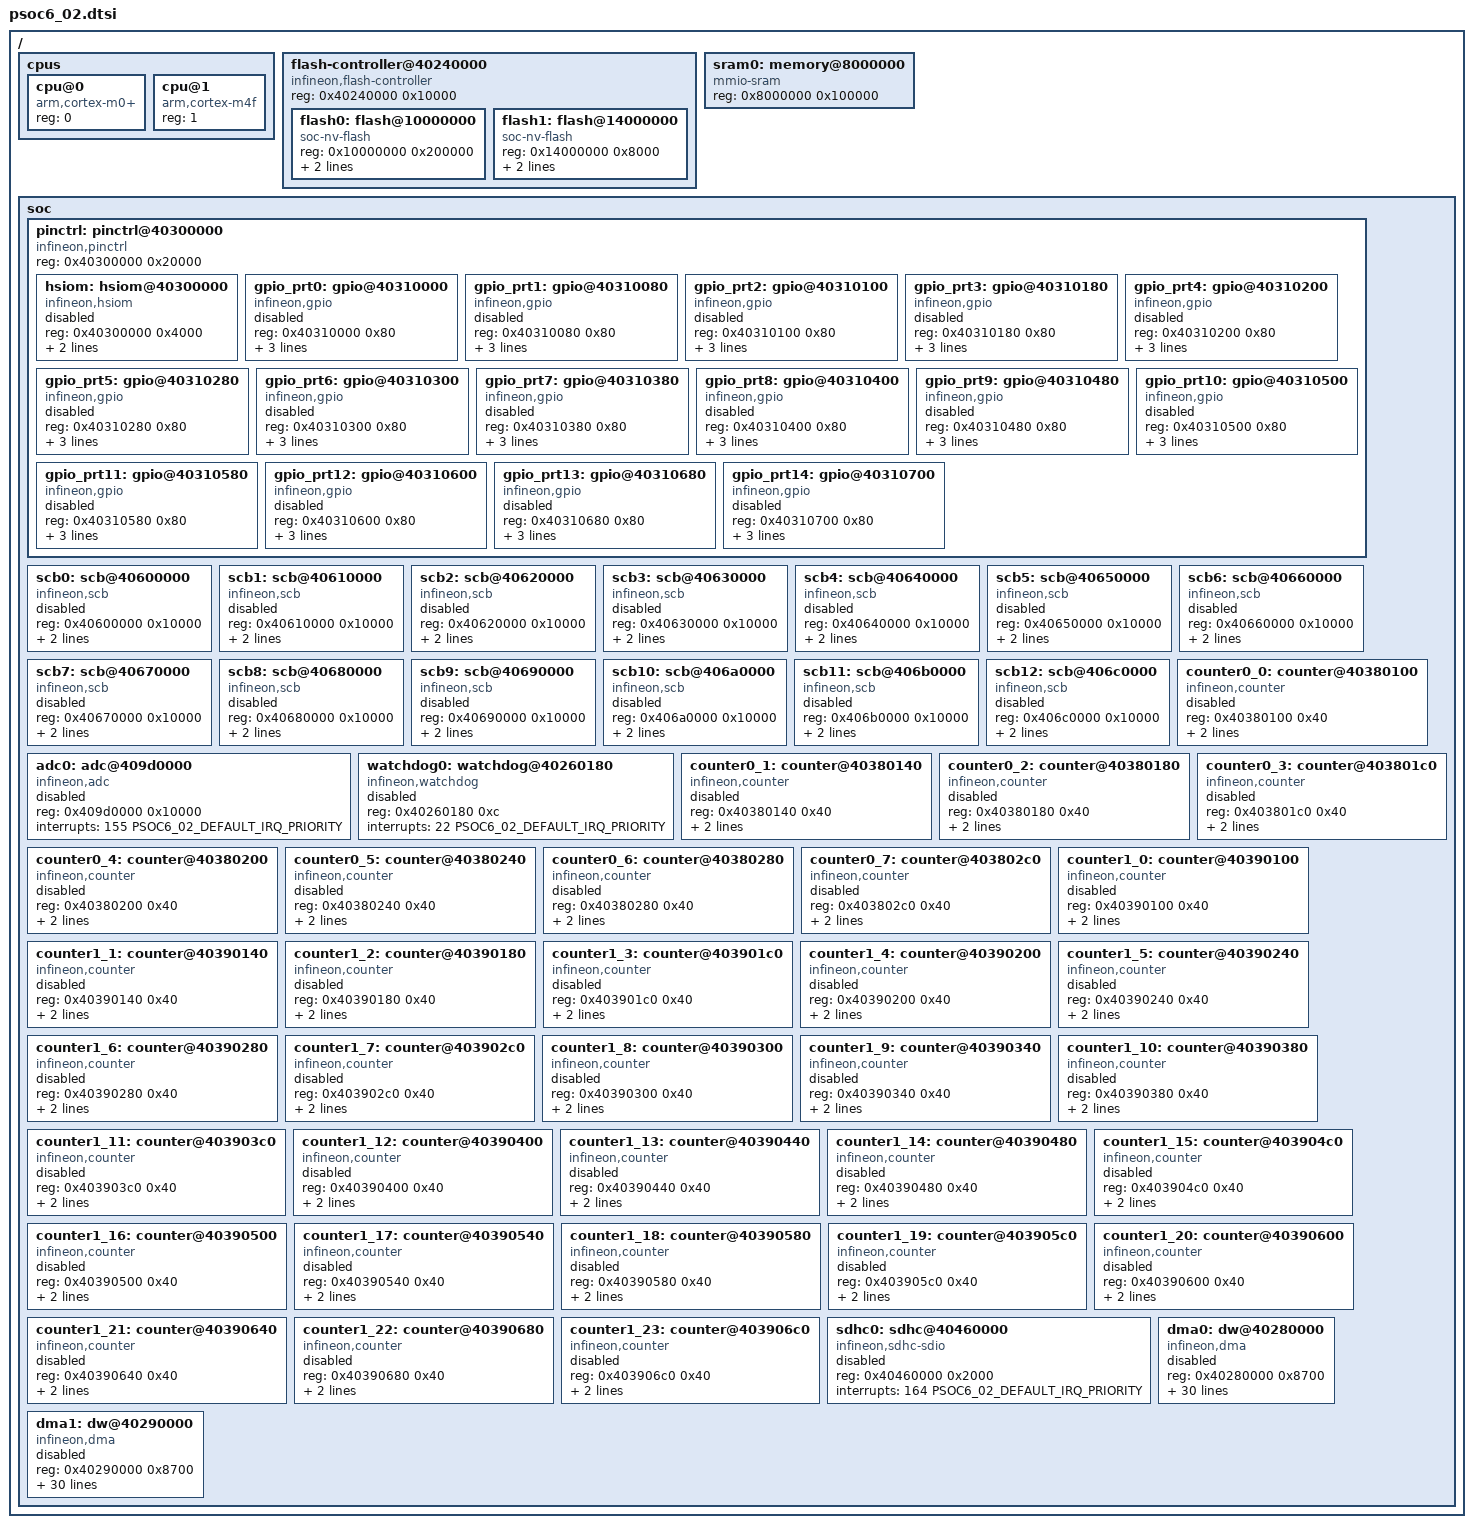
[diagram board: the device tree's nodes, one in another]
/*
 * Copyright (c) 2023 Cypress Semiconductor Corporation (an Infineon company) or
 * an affiliate of Cypress Semiconductor Corporation
 *
 * SPDX-License-Identifier: Apache-2.0
 */

#include <mem.h>

#ifndef PSOC6_02_DEFAULT_IRQ_PRIORITY
#define PSOC6_02_DEFAULT_IRQ_PRIORITY 6
#endif

/ {
	cpus {
		#address-cells = <1>;
		#size-cells = <0>;

		cpu@0 {
			device_type = "cpu";
			compatible = "arm,cortex-m0+";
			reg = <0>;
		};

		cpu@1 {
			device_type = "cpu";
			compatible = "arm,cortex-m4f";
			reg = <1>;
		};
	};

	flash-controller@40240000 {
		compatible = "infineon,flash-controller";
		reg = <0x40240000 0x10000>;
		#address-cells = <1>;
		#size-cells = <1>;

		flash0: flash@10000000 {
			compatible = "soc-nv-flash";
			reg = <0x10000000 0x200000>;
			write-block-size = <512>;
			erase-block-size = <512>;
		};

		flash1: flash@14000000 {
			compatible = "soc-nv-flash";
			reg = <0x14000000 0x8000>;
			write-block-size = <512>;
			erase-block-size = <512>;
		};
	};

	sram0: memory@8000000 {
		compatible = "mmio-sram";
		reg = <0x8000000 0x100000>;
	};

	soc {
		pinctrl: pinctrl@40300000 {
			compatible = "infineon,pinctrl";
			reg = <0x40300000 0x20000>;
			#address-cells = <1>;
			#size-cells = <0>;

			hsiom: hsiom@40300000 {
				compatible = "infineon,hsiom";
				reg = <0x40300000 0x4000>;
				interrupts = <15 PSOC6_02_DEFAULT_IRQ_PRIORITY>,
							<16 PSOC6_02_DEFAULT_IRQ_PRIORITY>;
				status = "disabled";
			};

			gpio_prt0: gpio@40310000 {
				compatible = "infineon,gpio";
				reg = <0x40310000 0x80>;
				interrupts = <0 PSOC6_02_DEFAULT_IRQ_PRIORITY>;
				gpio-controller;
				ngpios = <6>;
				status = "disabled";
				#gpio-cells = <2>;
			};

			gpio_prt1: gpio@40310080 {
				compatible = "infineon,gpio";
				reg = <0x40310080 0x80>;
				interrupts = <1 PSOC6_02_DEFAULT_IRQ_PRIORITY>;
				gpio-controller;
				ngpios = <6>;
				status = "disabled";
				#gpio-cells = <2>;
			};

			gpio_prt2: gpio@40310100 {
				compatible = "infineon,gpio";
				reg = <0x40310100 0x80>;
				interrupts = <2 PSOC6_02_DEFAULT_IRQ_PRIORITY>;
				gpio-controller;
				ngpios = <8>;
				status = "disabled";
				#gpio-cells = <2>;
			};

			gpio_prt3: gpio@40310180 {
				compatible = "infineon,gpio";
				reg = <0x40310180 0x80>;
				interrupts = <3 PSOC6_02_DEFAULT_IRQ_PRIORITY>;
				gpio-controller;
				ngpios = <6>;
				status = "disabled";
				#gpio-cells = <2>;
			};

			gpio_prt4: gpio@40310200 {
				compatible = "infineon,gpio";
				reg = <0x40310200 0x80>;
				interrupts = <4 PSOC6_02_DEFAULT_IRQ_PRIORITY>;
				gpio-controller;
				ngpios = <2>;
				status = "disabled";
				#gpio-cells = <2>;
			};

			gpio_prt5: gpio@40310280 {
				compatible = "infineon,gpio";
				reg = <0x40310280 0x80>;
				interrupts = <5 PSOC6_02_DEFAULT_IRQ_PRIORITY>;
				gpio-controller;
				ngpios = <8>;
				status = "disabled";
				#gpio-cells = <2>;
			};

			gpio_prt6: gpio@40310300 {
				compatible = "infineon,gpio";
				reg = <0x40310300 0x80>;
				interrupts = <6 PSOC6_02_DEFAULT_IRQ_PRIORITY>;
				gpio-controller;
				ngpios = <8>;
				status = "disabled";
				#gpio-cells = <2>;
			};

			gpio_prt7: gpio@40310380 {
				compatible = "infineon,gpio";
				reg = <0x40310380 0x80>;
				interrupts = <7 PSOC6_02_DEFAULT_IRQ_PRIORITY>;
				gpio-controller;
				ngpios = <8>;
				status = "disabled";
				#gpio-cells = <2>;
			};

			gpio_prt8: gpio@40310400 {
				compatible = "infineon,gpio";
				reg = <0x40310400 0x80>;
				interrupts = <8 PSOC6_02_DEFAULT_IRQ_PRIORITY>;
				gpio-controller;
				ngpios = <8>;
				status = "disabled";
				#gpio-cells = <2>;
			};

			gpio_prt9: gpio@40310480 {
				compatible = "infineon,gpio";
				reg = <0x40310480 0x80>;
				interrupts = <9 PSOC6_02_DEFAULT_IRQ_PRIORITY>;
				gpio-controller;
				ngpios = <8>;
				status = "disabled";
				#gpio-cells = <2>;
			};

			gpio_prt10: gpio@40310500 {
				compatible = "infineon,gpio";
				reg = <0x40310500 0x80>;
				interrupts = <10 PSOC6_02_DEFAULT_IRQ_PRIORITY>;
				gpio-controller;
				ngpios = <8>;
				status = "disabled";
				#gpio-cells = <2>;
			};

			gpio_prt11: gpio@40310580 {
				compatible = "infineon,gpio";
				reg = <0x40310580 0x80>;
				interrupts = <11 PSOC6_02_DEFAULT_IRQ_PRIORITY>;
				gpio-controller;
				ngpios = <8>;
				status = "disabled";
				#gpio-cells = <2>;
			};

			gpio_prt12: gpio@40310600 {
				compatible = "infineon,gpio";
				reg = <0x40310600 0x80>;
				interrupts = <12 PSOC6_02_DEFAULT_IRQ_PRIORITY>;
				gpio-controller;
				ngpios = <8>;
				status = "disabled";
				#gpio-cells = <2>;
			};

			gpio_prt13: gpio@40310680 {
				compatible = "infineon,gpio";
				reg = <0x40310680 0x80>;
				interrupts = <13 PSOC6_02_DEFAULT_IRQ_PRIORITY>;
				gpio-controller;
				ngpios = <8>;
				status = "disabled";
				#gpio-cells = <2>;
			};

			gpio_prt14: gpio@40310700 {
				compatible = "infineon,gpio";
				reg = <0x40310700 0x80>;
				interrupts = <14 PSOC6_02_DEFAULT_IRQ_PRIORITY>;
				gpio-controller;
				ngpios = <2>;
				status = "disabled";
				#gpio-cells = <2>;
			};
		};

		scb0: scb@40600000 {
			compatible = "infineon,scb";
			reg = <0x40600000 0x10000>;
			#address-cells = <1>;
			#size-cells = <0>;
			interrupts = <39 PSOC6_02_DEFAULT_IRQ_PRIORITY>;
			clk-dst = <0x0>;
			status = "disabled";
		};

		scb1: scb@40610000 {
			compatible = "infineon,scb";
			reg = <0x40610000 0x10000>;
			#address-cells = <1>;
			#size-cells = <0>;
			interrupts = <40 PSOC6_02_DEFAULT_IRQ_PRIORITY>;
			clk-dst = <0x1>;
			status = "disabled";
		};

		scb2: scb@40620000 {
			compatible = "infineon,scb";
			reg = <0x40620000 0x10000>;
			#address-cells = <1>;
			#size-cells = <0>;
			interrupts = <41 PSOC6_02_DEFAULT_IRQ_PRIORITY>;
			clk-dst = <0x2>;
			status = "disabled";
		};

		scb3: scb@40630000 {
			compatible = "infineon,scb";
			reg = <0x40630000 0x10000>;
			#address-cells = <1>;
			#size-cells = <0>;
			interrupts = <42 PSOC6_02_DEFAULT_IRQ_PRIORITY>;
			clk-dst = <0x3>;
			status = "disabled";
		};

		scb4: scb@40640000 {
			compatible = "infineon,scb";
			reg = <0x40640000 0x10000>;
			#address-cells = <1>;
			#size-cells = <0>;
			interrupts = <43 PSOC6_02_DEFAULT_IRQ_PRIORITY>;
			clk-dst = <0x4>;
			status = "disabled";
		};

		scb5: scb@40650000 {
			compatible = "infineon,scb";
			reg = <0x40650000 0x10000>;
			#address-cells = <1>;
			#size-cells = <0>;
			interrupts = <44 PSOC6_02_DEFAULT_IRQ_PRIORITY>;
			clk-dst = <0x5>;
			status = "disabled";
		};

		scb6: scb@40660000 {
			compatible = "infineon,scb";
			reg = <0x40660000 0x10000>;
			#address-cells = <1>;
			#size-cells = <0>;
			interrupts = <45 PSOC6_02_DEFAULT_IRQ_PRIORITY>;
			clk-dst = <0x6>;
			status = "disabled";
		};

		scb7: scb@40670000 {
			compatible = "infineon,scb";
			reg = <0x40670000 0x10000>;
			#address-cells = <1>;
			#size-cells = <0>;
			interrupts = <46 PSOC6_02_DEFAULT_IRQ_PRIORITY>;
			clk-dst = <0x7>;
			status = "disabled";
		};

		scb8: scb@40680000 {
			compatible = "infineon,scb";
			reg = <0x40680000 0x10000>;
			#address-cells = <1>;
			#size-cells = <0>;
			interrupts = <18 PSOC6_02_DEFAULT_IRQ_PRIORITY>;
			clk-dst = <0x8>;
			status = "disabled";
		};

		scb9: scb@40690000 {
			compatible = "infineon,scb";
			reg = <0x40690000 0x10000>;
			#address-cells = <1>;
			#size-cells = <0>;
			interrupts = <47 PSOC6_02_DEFAULT_IRQ_PRIORITY>;
			clk-dst = <0x9>;
			status = "disabled";
		};

		scb10: scb@406a0000 {
			compatible = "infineon,scb";
			reg = <0x406a0000 0x10000>;
			#address-cells = <1>;
			#size-cells = <0>;
			interrupts = <48 PSOC6_02_DEFAULT_IRQ_PRIORITY>;
			clk-dst = <0xa>;
			status = "disabled";
		};

		scb11: scb@406b0000 {
			compatible = "infineon,scb";
			reg = <0x406b0000 0x10000>;
			#address-cells = <1>;
			#size-cells = <0>;
			interrupts = <49 PSOC6_02_DEFAULT_IRQ_PRIORITY>;
			clk-dst = <0xb>;
			status = "disabled";
		};

		scb12: scb@406c0000 {
			compatible = "infineon,scb";
			reg = <0x406c0000 0x10000>;
			#address-cells = <1>;
			#size-cells = <0>;
			interrupts = <50 PSOC6_02_DEFAULT_IRQ_PRIORITY>;
			clk-dst = <0xc>;
			status = "disabled";
		};

		adc0: adc@409d0000 {
			compatible = "infineon,adc";
			reg = <0x409d0000 0x10000>;
			interrupts = <155 PSOC6_02_DEFAULT_IRQ_PRIORITY>;
			status = "disabled";
			#io-channel-cells = <1>;
		};

		watchdog0: watchdog@40260180 {
			compatible = "infineon,watchdog";
			reg = <0x40260180 0xc>;
			interrupts = <22 PSOC6_02_DEFAULT_IRQ_PRIORITY>;
			status = "disabled";
		};

		counter0_0: counter@40380100 {
			compatible = "infineon,counter";
			reg = <0x40380100 0x40>;
			interrupts = <123 PSOC6_02_DEFAULT_IRQ_PRIORITY>;
			resolution = <32>;
			status = "disabled";
		};

		counter0_1: counter@40380140 {
			compatible = "infineon,counter";
			reg = <0x40380140 0x40>;
			interrupts = <124 PSOC6_02_DEFAULT_IRQ_PRIORITY>;
			resolution = <32>;
			status = "disabled";
		};

		counter0_2: counter@40380180 {
			compatible = "infineon,counter";
			reg = <0x40380180 0x40>;
			interrupts = <125 PSOC6_02_DEFAULT_IRQ_PRIORITY>;
			resolution = <32>;
			status = "disabled";
		};

		counter0_3: counter@403801c0 {
			compatible = "infineon,counter";
			reg = <0x403801c0 0x40>;
			interrupts = <126 PSOC6_02_DEFAULT_IRQ_PRIORITY>;
			resolution = <32>;
			status = "disabled";
		};

		counter0_4: counter@40380200 {
			compatible = "infineon,counter";
			reg = <0x40380200 0x40>;
			interrupts = <127 PSOC6_02_DEFAULT_IRQ_PRIORITY>;
			resolution = <32>;
			status = "disabled";
		};

		counter0_5: counter@40380240 {
			compatible = "infineon,counter";
			reg = <0x40380240 0x40>;
			interrupts = <128 PSOC6_02_DEFAULT_IRQ_PRIORITY>;
			resolution = <32>;
			status = "disabled";
		};

		counter0_6: counter@40380280 {
			compatible = "infineon,counter";
			reg = <0x40380280 0x40>;
			interrupts = <129 PSOC6_02_DEFAULT_IRQ_PRIORITY>;
			resolution = <32>;
			status = "disabled";
		};

		counter0_7: counter@403802c0 {
			compatible = "infineon,counter";
			reg = <0x403802c0 0x40>;
			interrupts = <130 PSOC6_02_DEFAULT_IRQ_PRIORITY>;
			resolution = <32>;
			status = "disabled";
		};

		counter1_0: counter@40390100 {
			compatible = "infineon,counter";
			reg = <0x40390100 0x40>;
			interrupts = <131 PSOC6_02_DEFAULT_IRQ_PRIORITY>;
			resolution = <16>;
			status = "disabled";
		};

		counter1_1: counter@40390140 {
			compatible = "infineon,counter";
			reg = <0x40390140 0x40>;
			interrupts = <132 PSOC6_02_DEFAULT_IRQ_PRIORITY>;
			resolution = <16>;
			status = "disabled";
		};

		counter1_2: counter@40390180 {
			compatible = "infineon,counter";
			reg = <0x40390180 0x40>;
			interrupts = <133 PSOC6_02_DEFAULT_IRQ_PRIORITY>;
			resolution = <16>;
			status = "disabled";
		};

		counter1_3: counter@403901c0 {
			compatible = "infineon,counter";
			reg = <0x403901c0 0x40>;
			interrupts = <134 PSOC6_02_DEFAULT_IRQ_PRIORITY>;
			resolution = <16>;
			status = "disabled";
		};

		counter1_4: counter@40390200 {
			compatible = "infineon,counter";
			reg = <0x40390200 0x40>;
			interrupts = <135 PSOC6_02_DEFAULT_IRQ_PRIORITY>;
			resolution = <16>;
			status = "disabled";
		};

		counter1_5: counter@40390240 {
			compatible = "infineon,counter";
			reg = <0x40390240 0x40>;
			interrupts = <136 PSOC6_02_DEFAULT_IRQ_PRIORITY>;
			resolution = <16>;
			status = "disabled";
		};

		counter1_6: counter@40390280 {
			compatible = "infineon,counter";
			reg = <0x40390280 0x40>;
			interrupts = <137 PSOC6_02_DEFAULT_IRQ_PRIORITY>;
			resolution = <16>;
			status = "disabled";
		};

		counter1_7: counter@403902c0 {
			compatible = "infineon,counter";
			reg = <0x403902c0 0x40>;
			interrupts = <138 PSOC6_02_DEFAULT_IRQ_PRIORITY>;
			resolution = <16>;
			status = "disabled";
		};

		counter1_8: counter@40390300 {
			compatible = "infineon,counter";
			reg = <0x40390300 0x40>;
			interrupts = <139 PSOC6_02_DEFAULT_IRQ_PRIORITY>;
			resolution = <16>;
			status = "disabled";
		};

		counter1_9: counter@40390340 {
			compatible = "infineon,counter";
			reg = <0x40390340 0x40>;
			interrupts = <140 PSOC6_02_DEFAULT_IRQ_PRIORITY>;
			resolution = <16>;
			status = "disabled";
		};

		counter1_10: counter@40390380 {
			compatible = "infineon,counter";
			reg = <0x40390380 0x40>;
			interrupts = <141 PSOC6_02_DEFAULT_IRQ_PRIORITY>;
			resolution = <16>;
			status = "disabled";
		};

		counter1_11: counter@403903c0 {
			compatible = "infineon,counter";
			reg = <0x403903c0 0x40>;
			interrupts = <142 PSOC6_02_DEFAULT_IRQ_PRIORITY>;
			resolution = <16>;
			status = "disabled";
		};

		counter1_12: counter@40390400 {
			compatible = "infineon,counter";
			reg = <0x40390400 0x40>;
			interrupts = <143 PSOC6_02_DEFAULT_IRQ_PRIORITY>;
			resolution = <16>;
			status = "disabled";
		};

		counter1_13: counter@40390440 {
			compatible = "infineon,counter";
			reg = <0x40390440 0x40>;
			interrupts = <144 PSOC6_02_DEFAULT_IRQ_PRIORITY>;
			resolution = <16>;
			status = "disabled";
		};

		counter1_14: counter@40390480 {
			compatible = "infineon,counter";
			reg = <0x40390480 0x40>;
			interrupts = <145 PSOC6_02_DEFAULT_IRQ_PRIORITY>;
			resolution = <16>;
			status = "disabled";
		};

		counter1_15: counter@403904c0 {
			compatible = "infineon,counter";
			reg = <0x403904c0 0x40>;
			interrupts = <146 PSOC6_02_DEFAULT_IRQ_PRIORITY>;
			resolution = <16>;
			status = "disabled";
		};

		counter1_16: counter@40390500 {
			compatible = "infineon,counter";
			reg = <0x40390500 0x40>;
			interrupts = <147 PSOC6_02_DEFAULT_IRQ_PRIORITY>;
			resolution = <16>;
			status = "disabled";
		};

		counter1_17: counter@40390540 {
			compatible = "infineon,counter";
			reg = <0x40390540 0x40>;
			interrupts = <148 PSOC6_02_DEFAULT_IRQ_PRIORITY>;
			resolution = <16>;
			status = "disabled";
		};

		counter1_18: counter@40390580 {
			compatible = "infineon,counter";
			reg = <0x40390580 0x40>;
			interrupts = <149 PSOC6_02_DEFAULT_IRQ_PRIORITY>;
			resolution = <16>;
			status = "disabled";
		};

		counter1_19: counter@403905c0 {
			compatible = "infineon,counter";
			reg = <0x403905c0 0x40>;
			interrupts = <150 PSOC6_02_DEFAULT_IRQ_PRIORITY>;
			resolution = <16>;
			status = "disabled";
		};

		counter1_20: counter@40390600 {
			compatible = "infineon,counter";
			reg = <0x40390600 0x40>;
			interrupts = <151 PSOC6_02_DEFAULT_IRQ_PRIORITY>;
			resolution = <16>;
			status = "disabled";
		};

		counter1_21: counter@40390640 {
			compatible = "infineon,counter";
			reg = <0x40390640 0x40>;
			interrupts = <152 PSOC6_02_DEFAULT_IRQ_PRIORITY>;
			resolution = <16>;
			status = "disabled";
		};

		counter1_22: counter@40390680 {
			compatible = "infineon,counter";
			reg = <0x40390680 0x40>;
			interrupts = <153 PSOC6_02_DEFAULT_IRQ_PRIORITY>;
			resolution = <16>;
			status = "disabled";
		};

		counter1_23: counter@403906c0 {
			compatible = "infineon,counter";
			reg = <0x403906c0 0x40>;
			interrupts = <154 PSOC6_02_DEFAULT_IRQ_PRIORITY>;
			resolution = <16>;
			status = "disabled";
		};

		sdhc0: sdhc@40460000 {
			compatible = "infineon,sdhc-sdio";
			reg = <0x40460000 0x2000>;
			interrupts = <164 PSOC6_02_DEFAULT_IRQ_PRIORITY>;
			status = "disabled";
		};

		dma0: dw@40280000 {
			#dma-cells = <1>;
			compatible = "infineon,dma";
			reg = <0x40280000 0x8700>;
			dma-channels = <29>;
			interrupts = <56 PSOC6_02_DEFAULT_IRQ_PRIORITY>,  /* CH0 */
				     <57 PSOC6_02_DEFAULT_IRQ_PRIORITY>,  /* CH1 */
				     <58 PSOC6_02_DEFAULT_IRQ_PRIORITY>,  /* CH2 */
				     <59 PSOC6_02_DEFAULT_IRQ_PRIORITY>,  /* CH3 */
				     <60 PSOC6_02_DEFAULT_IRQ_PRIORITY>,  /* CH4 */
				     <61 PSOC6_02_DEFAULT_IRQ_PRIORITY>,  /* CH5 */
				     <62 PSOC6_02_DEFAULT_IRQ_PRIORITY>,  /* CH6 */
				     <63 PSOC6_02_DEFAULT_IRQ_PRIORITY>,  /* CH7 */
				     <64 PSOC6_02_DEFAULT_IRQ_PRIORITY>,  /* CH8 */
				     <65 PSOC6_02_DEFAULT_IRQ_PRIORITY>,  /* CH9 */
				     <66 PSOC6_02_DEFAULT_IRQ_PRIORITY>,  /* CH10 */
				     <67 PSOC6_02_DEFAULT_IRQ_PRIORITY>,  /* CH11 */
				     <68 PSOC6_02_DEFAULT_IRQ_PRIORITY>,  /* CH12 */
				     <69 PSOC6_02_DEFAULT_IRQ_PRIORITY>,  /* CH13 */
				     <70 PSOC6_02_DEFAULT_IRQ_PRIORITY>,  /* CH14 */
				     <71 PSOC6_02_DEFAULT_IRQ_PRIORITY>,  /* CH15 */
				     <72 PSOC6_02_DEFAULT_IRQ_PRIORITY>,  /* CH16 */
				     <73 PSOC6_02_DEFAULT_IRQ_PRIORITY>,  /* CH17 */
				     <74 PSOC6_02_DEFAULT_IRQ_PRIORITY>,  /* CH18 */
				     <75 PSOC6_02_DEFAULT_IRQ_PRIORITY>,  /* CH19 */
				     <76 PSOC6_02_DEFAULT_IRQ_PRIORITY>,  /* CH20 */
				     <77 PSOC6_02_DEFAULT_IRQ_PRIORITY>,  /* CH21 */
				     <78 PSOC6_02_DEFAULT_IRQ_PRIORITY>,  /* CH22 */
				     <79 PSOC6_02_DEFAULT_IRQ_PRIORITY>,  /* CH23 */
				     <80 PSOC6_02_DEFAULT_IRQ_PRIORITY>,  /* CH24 */
				     <81 PSOC6_02_DEFAULT_IRQ_PRIORITY>,  /* CH25 */
				     <82 PSOC6_02_DEFAULT_IRQ_PRIORITY>,  /* CH26 */
				     <83 PSOC6_02_DEFAULT_IRQ_PRIORITY>,  /* CH27 */
				     <84 PSOC6_02_DEFAULT_IRQ_PRIORITY>;  /* CH28 */
			status = "disabled";
		};

		dma1: dw@40290000 {
			#dma-cells = <1>;
			compatible = "infineon,dma";
			reg = <0x40290000 0x8700>;
			dma-channels = <29>;
			interrupts = <85 PSOC6_02_DEFAULT_IRQ_PRIORITY>,  /* CH0 */
				     <86 PSOC6_02_DEFAULT_IRQ_PRIORITY>,  /* CH1 */
				     <87 PSOC6_02_DEFAULT_IRQ_PRIORITY>,  /* CH2 */
				     <88 PSOC6_02_DEFAULT_IRQ_PRIORITY>,  /* CH3 */
				     <89 PSOC6_02_DEFAULT_IRQ_PRIORITY>,  /* CH4 */
				     <90 PSOC6_02_DEFAULT_IRQ_PRIORITY>,  /* CH5 */
				     <91 PSOC6_02_DEFAULT_IRQ_PRIORITY>,  /* CH6 */
				     <92 PSOC6_02_DEFAULT_IRQ_PRIORITY>,  /* CH7 */
				     <93 PSOC6_02_DEFAULT_IRQ_PRIORITY>,  /* CH8 */
				     <94 PSOC6_02_DEFAULT_IRQ_PRIORITY>,  /* CH9 */
				     <95 PSOC6_02_DEFAULT_IRQ_PRIORITY>,  /* CH10 */
				     <96 PSOC6_02_DEFAULT_IRQ_PRIORITY>,  /* CH11 */
				     <97 PSOC6_02_DEFAULT_IRQ_PRIORITY>,  /* CH12 */
				     <98 PSOC6_02_DEFAULT_IRQ_PRIORITY>,  /* CH13 */
				     <99 PSOC6_02_DEFAULT_IRQ_PRIORITY>,  /* CH14 */
				     <100 PSOC6_02_DEFAULT_IRQ_PRIORITY>,  /* CH15 */
				     <101 PSOC6_02_DEFAULT_IRQ_PRIORITY>,  /* CH16 */
				     <102 PSOC6_02_DEFAULT_IRQ_PRIORITY>,  /* CH17 */
				     <103 PSOC6_02_DEFAULT_IRQ_PRIORITY>,  /* CH18 */
				     <104 PSOC6_02_DEFAULT_IRQ_PRIORITY>,  /* CH19 */
				     <105 PSOC6_02_DEFAULT_IRQ_PRIORITY>,  /* CH20 */
				     <106 PSOC6_02_DEFAULT_IRQ_PRIORITY>,  /* CH21 */
				     <107 PSOC6_02_DEFAULT_IRQ_PRIORITY>,  /* CH22 */
				     <108 PSOC6_02_DEFAULT_IRQ_PRIORITY>,  /* CH23 */
				     <109 PSOC6_02_DEFAULT_IRQ_PRIORITY>,  /* CH24 */
				     <110 PSOC6_02_DEFAULT_IRQ_PRIORITY>,  /* CH25 */
				     <111 PSOC6_02_DEFAULT_IRQ_PRIORITY>,  /* CH26 */
				     <112 PSOC6_02_DEFAULT_IRQ_PRIORITY>,  /* CH27 */
				     <113 PSOC6_02_DEFAULT_IRQ_PRIORITY>;  /* CH28 */
			status = "disabled";
		};
	};
};
